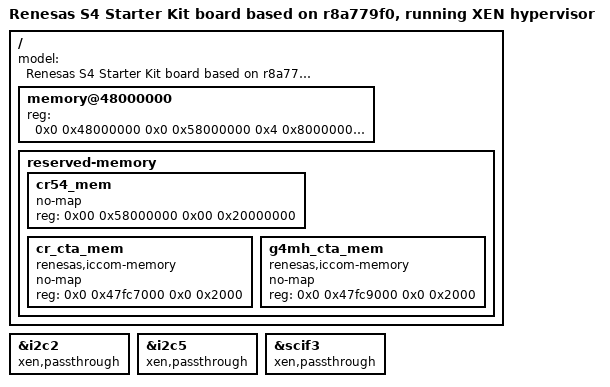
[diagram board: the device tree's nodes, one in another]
#include "r8a779f0-s4sk.dts"
#include "xen-chosen.dtsi"
#include "r8a779f0-xen.dts"

/ {

	model = "Renesas S4 Starter Kit board based on r8a779f0, running XEN hypervisor";

	/* Workaround U-Boot issue with memory nodes duplication */
	/delete-node/ memory@48000000;
	/delete-node/ memory@480000000;
	memory@48000000 {
		device_type = "memory";
		/* first 128MB is reserved for secure area. */
		reg = <0x0 0x48000000 0x0 0x58000000
		       0x4 0x80000000 0x0 0x80000000>;
	};

	reserved-memory {
		#address-cells = <2>;
		#size-cells = <2>;
		ranges;

		cr54_mem {
			no-map;
			reg = <0x00 0x58000000 0x00 0x20000000>;
		};

		/* ICCOM CR Shared memory */
		cr_cta_mem {
			compatible = "renesas,iccom-memory";
			no-map;
			reg = <0x0 0x47fc7000 0x0 0x2000>;
		};

		/* ICCOM G4MHA Shared memory */
		g4mh_cta_mem {
			compatible = "renesas,iccom-memory";
			no-map;
			reg = <0x0 0x47fc9000 0x0 0x2000>;
		};
	};
};

&i2c2			{ xen,passthrough; };
&i2c5			{ xen,passthrough; };
&scif3			{ xen,passthrough; };

